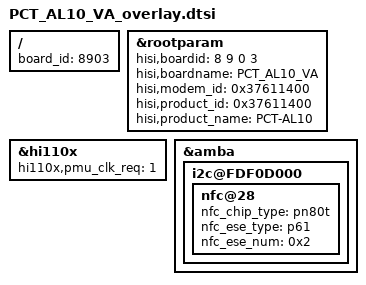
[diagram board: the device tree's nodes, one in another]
/**
 * Copyright (C) 2014 Hisilicon Ltd.
 *
 *  This program is free software; you can redistribute it and/or modify
 *  it under the terms of the GNU General Public License version 2 as
 *  publishhed by the Free Software Foundation.
 */

/include/ "PCT_TL00_VA_overlay.dtsi"

/ {
    board_id = <8903>;
};

	&rootparam{
		hisi,boardid = <8 9 0 3>;
		hisi,boardname = "PCT_AL10_VA";
		hisi,modem_id = <0x37611400>;
		hisi,product_id = <0x37611400>;
		hisi,product_name = "PCT-AL10";
	};

    /*hisi power*/
    &hi110x {
        hi110x,pmu_clk_req = <1>;
    };

	&amba {

		i2c@FDF0D000 {
			nfc@28{
				nfc_chip_type = "pn80t";
				nfc_ese_type = "p61";
				nfc_ese_num = <0x2>;
			};
		};
	};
